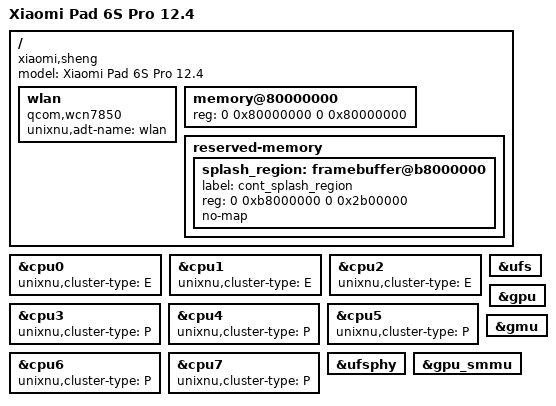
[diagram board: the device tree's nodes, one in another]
// SPDX-License-Identifier: BSD-3-Clause
/dts-v1/;
/include/ "sm8550.dtsi"

/ {
    model = "Xiaomi Pad 6S Pro 12.4";
    compatible = "xiaomi,sheng", "qcom,sm8550";

    // Export the radio before launchd evaluates wifid's device-tree condition.
    // WifiProbe owns PCIe resources and fills local-mac-address at runtime.
    wlan {
        compatible = "qcom,wcn7850";
        unixnu,adt-name = "wlan";
        status = "okay";
    };

    memory@80000000 {
        device_type = "memory";
        reg = <0 0x80000000 0 0x80000000>;
    };

    reserved-memory {
        #address-cells = <2>;
        #size-cells = <2>;
        ranges;
        splash_region: framebuffer@b8000000 {
            label = "cont_splash_region";
            reg = <0 0xb8000000 0 0x2b00000>;
            no-map;
        };
    };
};

// The scheduler runs the A510 cores as an E cluster and the others as a P cluster.
&cpu0 { unixnu,cluster-type = "E"; };
&cpu1 { unixnu,cluster-type = "E"; };
&cpu2 { unixnu,cluster-type = "E"; };
&cpu3 { unixnu,cluster-type = "P"; };
&cpu4 { unixnu,cluster-type = "P"; };
&cpu5 { unixnu,cluster-type = "P"; };
&cpu6 { unixnu,cluster-type = "P"; };
&cpu7 { unixnu,cluster-type = "P"; };
&ufs { status = "okay"; };
&ufsphy { status = "okay"; };
&gpu { status = "okay"; };
&gmu { status = "okay"; };
&gpu_smmu { status = "okay"; };
